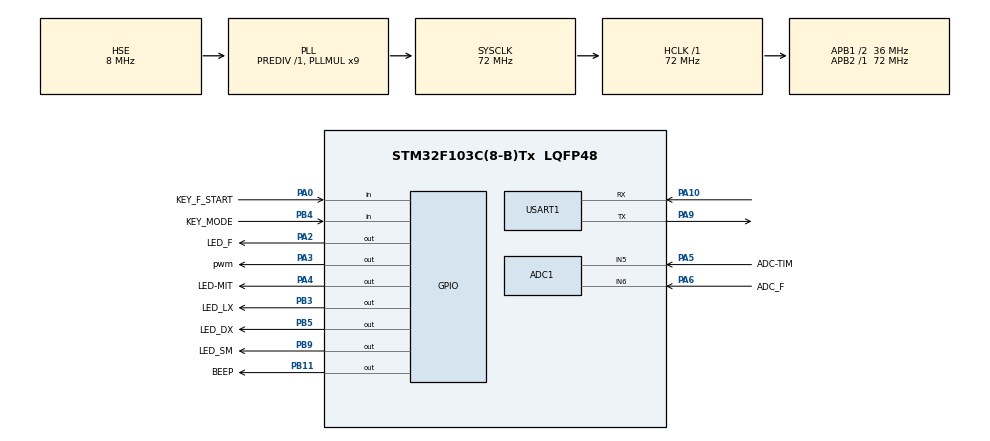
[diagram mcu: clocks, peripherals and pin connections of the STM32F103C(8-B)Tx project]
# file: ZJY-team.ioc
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ADC1.Channel-0\#ChannelRegularConversion=ADC_CHANNEL_5
ADC1.NbrOfConversion=1
ADC1.NbrOfConversionFlag=1
ADC1.Rank-0\#ChannelRegularConversion=1
ADC1.SamplingTime-0\#ChannelRegularConversion=ADC_SAMPLETIME_1CYCLE_5
ADC1.master=1
Mcu.Family=STM32F1
Mcu.Name=STM32F103C(8-B)Tx
Mcu.Package=LQFP48
NVIC.ADC1_2_IRQn=true\:0\:0\:false\:false\:true\:true\:true
NVIC.PriorityGroup=NVIC_PRIORITYGROUP_2
NVIC.TIM1_UP_IRQn=true\:0\:0\:false\:false\:true\:true\:true
PA0-WKUP.GPIO_Label=KEY_F_START
PA0-WKUP.GPIO_PuPd=GPIO_PULLUP
PA0-WKUP.Signal=GPIO_Input
PA10.Mode=Asynchronous
PA10.Signal=USART1_RX
PA13.Mode=Serial_Wire
PA13.Signal=SYS_JTMS-SWDIO
PA14.Mode=Serial_Wire
PA14.Signal=SYS_JTCK-SWCLK
PA2.GPIO_Label=LED_F
PA2.GPIO_PuPd=GPIO_PULLUP
PA2.Signal=GPIO_Output
PA3.GPIO_Label=pwm
PA3.GPIO_PuPd=GPIO_PULLUP
PA3.GPIO_Speed=GPIO_SPEED_FREQ_HIGH
PA3.PinState=GPIO_PIN_RESET
PA3.Signal=GPIO_Output
PA4.GPIO_Label=LED-MIT
PA4.GPIO_PuPd=GPIO_PULLUP
PA4.Signal=GPIO_Output
PA5.GPIO_Label=ADC-TIM
PA5.Signal=ADCx_IN5
PA6.GPIO_Label=ADC_F
PA6.Signal=ADCx_IN6
PA9.Mode=Asynchronous
PA9.Signal=USART1_TX
PB11.GPIO_Label=BEEP
PB11.GPIO_PuPd=GPIO_PULLUP
PB11.PinState=GPIO_PIN_RESET
PB11.Signal=GPIO_Output
PB3.GPIO_Label=LED_LX
PB3.GPIO_PuPd=GPIO_PULLUP
PB3.Signal=GPIO_Output
PB4.GPIO_Label=KEY_MODE
PB4.GPIO_PuPd=GPIO_PULLUP
PB4.Signal=GPIO_Input
PB5.GPIO_Label=LED_DX
PB5.GPIO_PuPd=GPIO_PULLUP
PB5.Signal=GPIO_Output
PB9.GPIO_Label=LED_SM
PB9.GPIO_PuPd=GPIO_PULLUP
PB9.Signal=GPIO_Output
PD0-OSC_IN.Mode=HSE-External-Oscillator
PD0-OSC_IN.Signal=RCC_OSC_IN
PD1-OSC_OUT.Mode=HSE-External-Oscillator
PD1-OSC_OUT.Signal=RCC_OSC_OUT
ProjectManager.HeapSize=0x200
ProjectManager.StackSize=0x400
ProjectManager.TargetToolchain=SW4STM32
RCC.ADCPresc=RCC_ADCPCLK2_DIV6
RCC.AHBFreq_Value=72000000
RCC.APB1CLKDivider=RCC_HCLK_DIV2
RCC.APB1Freq_Value=36000000
RCC.APB1TimFreq_Value=72000000
RCC.APB2Freq_Value=72000000
RCC.APB2TimFreq_Value=72000000
RCC.HCLKFreq_Value=72000000
RCC.PLLMUL=RCC_PLL_MUL9
RCC.PLLSourceVirtual=RCC_PLLSOURCE_HSE
RCC.SYSCLKFreq_VALUE=72000000
RCC.SYSCLKSource=RCC_SYSCLKSOURCE_PLLCLK
RCC.USBFreq_Value=72000000
SH.ADCx_IN5.0=ADC1_IN5,IN5
SH.ADCx_IN6.0=ADC1_IN6,IN6
TIM1.AutoReloadPreload=TIM_AUTORELOAD_PRELOAD_ENABLE
TIM1.Period=200-1
TIM1.Prescaler=72-1
TIM1.TIM_MasterOutputTrigger=TIM_TRGO_UPDATE
USART1.VirtualMode=VM_ASYNC
VP_TIM1_VS_ClockSourceINT.Mode=Internal
board=custom

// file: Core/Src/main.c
/* USER CODE BEGIN Header */
/**
  ******************************************************************************
  * @file           : main.c
  * @brief          : Main program body
  ******************************************************************************
  * @attention
  *
  * <h2><center>&copy; Copyright (c) 2022 STMicroelectronics.
  * All rights reserved.</center></h2>
  *
  * This software component is licensed by ST under BSD 3-Clause license,
  * the "License"; You may not use this file except in compliance with the
  * License. You may obtain a copy of the License at:
  *                        opensource.org/licenses/BSD-3-Clause
  *
  ******************************************************************************
  */
/* USER CODE END Header */
#include "main.h"
#include "adc.h"
#include "tim.h"
#include "usart.h"
#include "gpio.h"

/* USER CODE BEGIN Includes */
#include "ZJY/ZJY.h"
#include "ZJY/retarget.h"
/* USER CODE END Includes */

void SystemClock_Config(void);

int main(void)
{

  /* MCU Configuration--------------------------------------------------------*/

  /* Reset of all peripherals, Initializes the Flash interface and the Systick. */
  HAL_Init();

  /* Configure the system clock */
  SystemClock_Config();

  /* Initialize all configured peripherals */
  MX_GPIO_Init();
  MX_ADC1_Init();
  MX_TIM1_Init();
  MX_USART1_UART_Init();
  /* USER CODE BEGIN 2 */
  RetargetInit(&huart1);
  uint8_t start_state = 0;
  //printf("open");
    if (First_Check(1,0,0,0,0,1,0,200,0))///through the check
    {
        start_state = 1;
    }
  /* USER CODE END 2 */

  /* Infinite loop */
  /* USER CODE BEGIN WHILE */
  while (1 && start_state)
  {
    /* USER CODE END WHILE */

    /* USER CODE BEGIN 3 */
      Cur_Check();
      LED_Work();
      PWM_Start();
  }
  ///can not work

  /* USER CODE END 3 */
}

void SystemClock_Config(void)
{
  RCC_OscInitTypeDef RCC_OscInitStruct = {0};
  RCC_ClkInitTypeDef RCC_ClkInitStruct = {0};
  RCC_PeriphCLKInitTypeDef PeriphClkInit = {0};

  /** Initializes the RCC Oscillators according to the specified parameters
  * in the RCC_OscInitTypeDef structure.
  */
  RCC_OscInitStruct.OscillatorType = RCC_OSCILLATORTYPE_HSE;
  RCC_OscInitStruct.HSEState = RCC_HSE_ON;
  RCC_OscInitStruct.HSEPredivValue = RCC_HSE_PREDIV_DIV1;
  RCC_OscInitStruct.HSIState = RCC_HSI_ON;
  RCC_OscInitStruct.PLL.PLLState = RCC_PLL_ON;
  RCC_OscInitStruct.PLL.PLLSource = RCC_PLLSOURCE_HSE;
  RCC_OscInitStruct.PLL.PLLMUL = RCC_PLL_MUL9;
  if (HAL_RCC_OscConfig(&RCC_OscInitStruct) != HAL_OK)
  {
    Error_Handler();
  }
  /** Initializes the CPU, AHB and APB buses clocks
  */
  RCC_ClkInitStruct.ClockType = RCC_CLOCKTYPE_HCLK|RCC_CLOCKTYPE_SYSCLK
                              |RCC_CLOCKTYPE_PCLK1|RCC_CLOCKTYPE_PCLK2;
  RCC_ClkInitStruct.SYSCLKSource = RCC_SYSCLKSOURCE_PLLCLK;
  RCC_ClkInitStruct.AHBCLKDivider = RCC_SYSCLK_DIV1;
  RCC_ClkInitStruct.APB1CLKDivider = RCC_HCLK_DIV2;
  RCC_ClkInitStruct.APB2CLKDivider = RCC_HCLK_DIV1;

  if (HAL_RCC_ClockConfig(&RCC_ClkInitStruct, FLASH_LATENCY_2) != HAL_OK)
  {
    Error_Handler();
  }
  PeriphClkInit.PeriphClockSelection = RCC_PERIPHCLK_ADC;
  PeriphClkInit.AdcClockSelection = RCC_ADCPCLK2_DIV6;
  if (HAL_RCCEx_PeriphCLKConfig(&PeriphClkInit) != HAL_OK)
  {
    Error_Handler();
  }
}

void Error_Handler(void)
{
  __disable_irq();
  while (1)
  {
  }
}

/************************ (C) COPYRIGHT STMicroelectronics *****END OF FILE****/
